# A31G12x_series register map
Vendor: ABOV Semiconductor Co., Ltd.; Series: A31G12x_series; File version: 1.0
CPU: CM0PLUS r0p1, little endian, no MPU, no FPU, VTOR, 2 interrupt priority bits
Registers are 32-bit, read-write, reset 0x0 unless marked. A register's access mark holds for its fields unless they carry their own. Offsets are from the block's base; [hi:lo] are bit positions; {n}, {i} and the like mark numbered series.

## SCUCG — CLCOK GENERATION
Base 0x40001800
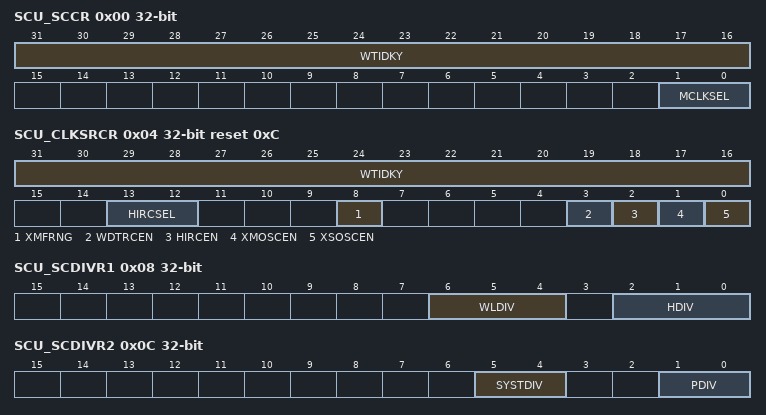
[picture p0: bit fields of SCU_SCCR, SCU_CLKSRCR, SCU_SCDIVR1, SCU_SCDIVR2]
0x00 SCU_SCCR — System Clock Control Register
  [31:16] WTIDKY wo — Write Identification Key. On writes, write 0x570A to these bits, otherwise the write is ignored.
  [1:0] MCLKSEL — Main Clock Selection bits, MCLK
    0=MCLK_HIRC (High frequency Internal RC oscillator (40MHz), HIRC); 1=MCLK_XMOSC (External main oscillator (2 - 40MHz), XMOSC); 2=MCLK_XSOSC (External sub oscillator (32.768kHz), XSOSC); 3=MCLK_WDTRC (Internal watch-dog timer RC oscillator (40kHz), WDTRC)
0x04 SCU_CLKSRCR reset 0xC — Clock Source Control Register
  [31:16] WTIDKY wo — Write Identification Key. On writes, write 0xA507 to these bits, otherwise the write is ignored.
  [13:12] HIRCSEL — HIRC Frequency Selection bits
    0=HIRC_40MHz (40MHz HIRC); 1=HIRC_20MHz (20MHz HIRC); 2=HIRC_10MHz (10MHz HIRC); 3=HIRC_5MHz (5MHz HIRC)
  [8] XMFRNG — External Main Oscillator Frequency Range Selection bit
    0=XMOSC_XTAL (x-tal for XMOSC, 2 to 16MHz); 1=XMOSC_EXTCLK (External clock for XMOSC, 2MHz to 40MHz)
  [3] WDTRCEN — WDTRC Enable bit, Watch-dog timer RC oscillator
    0=DISABLE_WDTRC; 1=ENABLE_WDTRC
  [2] HIRCEN — HIRC Enable bit, High frequency internal RC oscillator
    0=DISABLE_HIRC; 1=ENABLE_HIRC
  [1] XMOSCEN — XMOSC Enable bit, External main oscillator
    0=DISABLE_XMOSC; 1=ENABLE_XMOSC
  [0] XSOSCEN — XSOSC Enable bit, External sub oscillator
    0=DISABLE_XSOSC; 1=ENABLE_XSOSC
0x08 SCU_SCDIVR1 — System Clock Divide Register 1
  [6:4] WLDIV — Clock Divide bits for Watch Timer and LCD Driver, Divider 2
    0=MCLK/64; 1=MCLK/128; 2=MCLK/256; 3=MCLK/512; 4=MCLK/1024
  [2:0] HDIV — Clock Divide bits for HCLK, Divider 0
    0=MCLK/16; 1=MCLK/8; 2=MCLK/4; 3=MCLK/2; 4=MCLK/1
0x0C SCU_SCDIVR2 — System Clock Divide Register 2
  [5:4] SYSTDIV — Clock Divide bits for SysTick Timer, Divider 3
    0=HCLK/1; 1=HCLK/2; 2=HCLK/4; 3=HCLK/8
  [1:0] PDIV — Clock Divide bits for PCLK, Divider 1
    0=HCLK/1; 1=HCLK/2; 2=HCLK/4; 3=HCLK/8
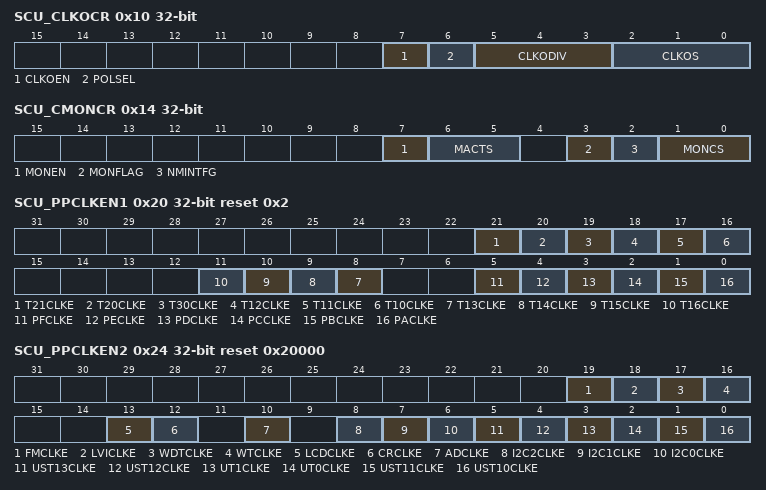
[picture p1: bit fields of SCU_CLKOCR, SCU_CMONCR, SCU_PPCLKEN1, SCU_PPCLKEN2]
0x10 SCU_CLKOCR — Clock Output Control Register
  [7] CLKOEN — Clock Output Enable bit
  [6] POLSEL — Clock Output Polarity Selection bit when disable
  [5:3] CLKODIV — Output Clock Divide bits, Divider 4
  [2:0] CLKOS — Clock Output Selection bits
0x14 SCU_CMONCR — Clock Monitoring Control Register
  [7] MONEN — Clock Monitoring Enable bit
  [6:5] MACTS — Clock Monitoring Action Selection bits
  [3] MONFLAG — Clock Monitoring Result Flag bit (Except the MCLK is selected for monitoring)
  [2] NMINTFG — Clock Monitoring Interrupt Flag bit (only during the MCLK is selected for monitoring)
  [1:0] MONCS — Monitored Clock Selection bits
0x20 SCU_PPCLKEN1 reset 0x2 — Peripheral Clock Enable Register 1
  [21] T21CLKE — Timer 21 Clock Enable bit
  [20] T20CLKE — Timer 20 Clock Enable bit
  [19] T30CLKE — Timer 30 Clock Enable bit
  [18] T12CLKE — Timer 12 Clock Enable bit
  [17] T11CLKE — Timer 11 Clock Enable bit
  [16] T10CLKE — Timer 10 Clock Enable bit
  [n-5] T{n}CLKE (n=13..16) — Timer {n} Clock Enable bit
  [5] PFCLKE — Port F Clock Enable bit
  [4] PECLKE — Port E Clock Enable bit
  [3] PDCLKE — Port D Clock Enable bit
  [2] PCCLKE — Port C Clock Enable bit
  [1] PBCLKE — Port B Clock Enable bit
  [0] PACLKE — Port A Clock Enable bit
0x24 SCU_PPCLKEN2 reset 0x20000 — Peripheral Clock Enable Register 2
  [19] FMCLKE — Flash Memory Control Clock Enable bit
  [18] LVICLKE — LVI (Low Voltage Indicator) Clock Enable bit
  [17] WDTCLKE — WDT (Watch-dog Timer) Clock Enable bit
  [16] WTCLKE — WT (Watch Timer) Clock Enable bit
  [13] LCDCLKE — LCD Controller Clock Enable bit
  [12] CRCLKE — CRC (Cyclic Redundancy Check) Clock Enable bit
  [10] ADCLKE — A/DC (Analog to Digital Converter) Clock Enable bit
  [8] I2C2CLKE — I2C2 (Inter-integrated Circuit) Clock Enable bit
  [7] I2C1CLKE — I2C1 (Inter-integrated Circuit) Clock Enable bit
  [6] I2C0CLKE — I2C0 (Inter-integrated Circuit) Clock Enable bit
  [5] UST13CLKE — USART13 Clock Enable bit
  [4] UST12CLKE — USART12 Clock Enable bit
  [3] UT1CLKE — UART1 Clock Enable bit
  [2] UT0CLKE — UART0 Clock Enable bit
  [1] UST11CLKE — USART11 Clock Enable bit
  [0] UST10CLKE — USART10 Clock Enable bit
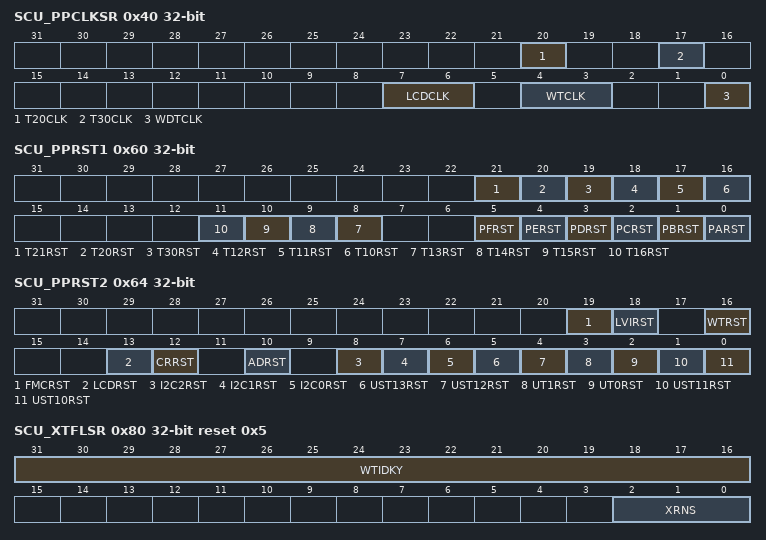
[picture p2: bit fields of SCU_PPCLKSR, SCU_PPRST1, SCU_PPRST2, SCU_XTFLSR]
0x40 SCU_PPCLKSR — Peripheral Clock Selection Register
  [20] T20CLK — Timer 20 Clock Selection bit
  [17] T30CLK — Timer 30 Clock Selection bit
  [7:6] LCDCLK — LCD Driver Clock Selection bit
  [4:3] WTCLK — Watch Timer Clock Selection bit
  [0] WDTCLK — Watch-dog Timer Clock Selection bit
0x60 SCU_PPRST1 — Peripheral Reset Register 1
  [21] T21RST — Timer 21 Reset bit
  [20] T20RST — Timer 20 Reset bit
  [19] T30RST — Timer 30 Reset bit
  [18] T12RST — Timer 12 Reset bit
  [17] T11RST — Timer 11 Reset bit
  [16] T10RST — Timer 10 Reset bit
  [n-5] T{n}RST (n=13..16) — Timer {n} Reset bit
  [5] PFRST — Port F Reset bit
  [4] PERST — Port E Reset bit
  [3] PDRST — Port D Reset bit
  [2] PCRST — Port C Reset bit
  [1] PBRST — Port B Reset bit
  [0] PARST — Port A Reset bit
0x64 SCU_PPRST2 — Peripheral Reset Register 2
  [19] FMCRST — Flash Memory Control Reset bit
  [18] LVIRST — LVI (Low Voltage Indicator) Reset bit
  [16] WTRST — WT (Watch Timer) Reset bit
  [13] LCDRST — LCD Controller Reset bit
  [12] CRRST — CRC (Cyclic Redundancy Check) Reset bit
  [10] ADRST — A/DC (Analog to Digital Converter) Reset bit
  [8] I2C2RST — I2C2 (Inter-integrated Circuit) Reset bit
  [7] I2C1RST — I2C1 (Inter-integrated Circuit) Reset bit
  [6] I2C0RST — I2C0 (Inter-integrated Circuit) Reset bit
  [5] UST13RST — USART13 Reset bit
  [4] UST12RST — USART12 Reset bit
  [3] UT1RST — UART1 Reset bit
  [2] UT0RST — UART0 Reset bit
  [1] UST11RST — USART11 Reset bit
  [0] UST10RST — USART10 Reset bit
0x80 SCU_XTFLSR reset 0x5 — X-tal Filter Selection Register
  [31:16] WTIDKY wo — Write Identification Key. On writes, write 0x9B37 to these bits, otherwise the write is ignored.
  [2:0] XRNS — External Main Oscillator Filter Selection bits.
